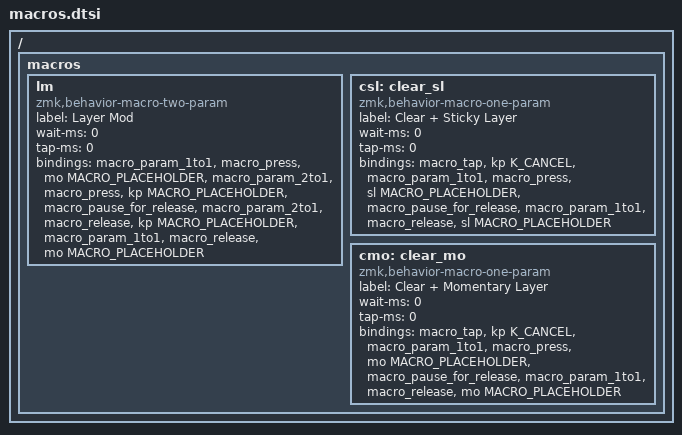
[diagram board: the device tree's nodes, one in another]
/ {
  macros {
    /*
      Temporarily switches to a layer (&mo) while a modifier is held. This is
      an implementation of QMK's `LM()` using ZMK's parameterized macros.

      Params:
        1. Layer to switch to
        2. Modifier to press while layer is active

      Example:
        `&lm L1 LSHIFT`
     */
    /omit-if-no-ref/ lm: lm {
      label = "Layer Mod";
      wait-ms = <0>;
      tap-ms = <0>;
      compatible = "zmk,behavior-macro-two-param";
      #binding-cells = <2>;
      bindings = <&macro_param_1to1>,
        <&macro_press &mo MACRO_PLACEHOLDER>,
        <&macro_param_2to1>,
        <&macro_press &kp MACRO_PLACEHOLDER>,
        <&macro_pause_for_release>,
        <&macro_param_2to1>,
        <&macro_release &kp MACRO_PLACEHOLDER>,
        <&macro_param_1to1>,
        <&macro_release &mo MACRO_PLACEHOLDER>;
    };

    /*
      Practically identical to &sl, except it triggers a `K_CANCEL` right before to clear
      any active smart layers. This prevents nested/stacked layer activation when needed.

      Params:
        1. Layer to switch to

      Example:
        `&csl L1`
     */
    /omit-if-no-ref/ csl: clear_sl {
      label = "Clear + Sticky Layer";
      wait-ms = <0>;
      tap-ms = <0>;
      compatible = "zmk,behavior-macro-one-param";
      #binding-cells = <1>;
      bindings = <&macro_tap &kp K_CANCEL>,
        <&macro_param_1to1>,
        <&macro_press &sl MACRO_PLACEHOLDER>,
        <&macro_pause_for_release>,
        <&macro_param_1to1>,
        <&macro_release &sl MACRO_PLACEHOLDER>;
    };

    /*
      Practically identical to &mo, except it triggers a `K_CANCEL` right before to clear
      any active smart layers. This prevents nested/stacked layer activation when needed.
      It's also useful to maintain more consistent expectations when holding a cancel/exit layer
      key from a smart layer.

      Params:
        1. Layer to switch to

      Example:
        `&cmo L1`
     */
    /omit-if-no-ref/ cmo: clear_mo {
      label = "Clear + Momentary Layer";
      wait-ms = <0>;
      tap-ms = <0>;
      compatible = "zmk,behavior-macro-one-param";
      #binding-cells = <1>;
      bindings = <&macro_tap &kp K_CANCEL>,
        <&macro_param_1to1>,
        <&macro_press &mo MACRO_PLACEHOLDER>,
        <&macro_pause_for_release>,
        <&macro_param_1to1>,
        <&macro_release &mo MACRO_PLACEHOLDER>;
    };
  };
};
